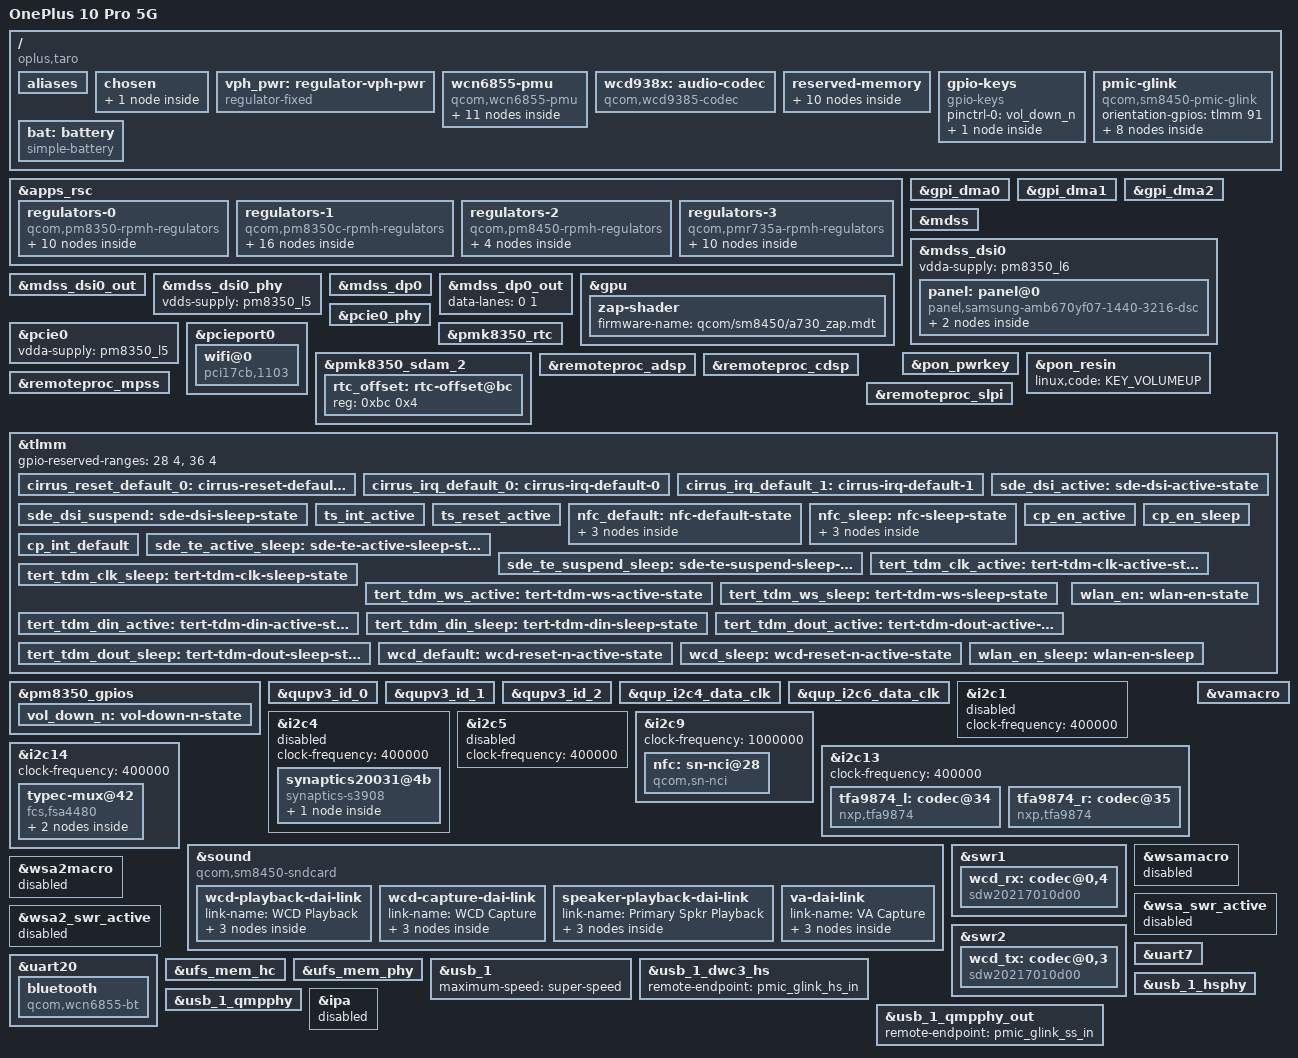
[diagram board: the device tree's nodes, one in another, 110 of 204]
// SPDX-License-Identifier: GPL-2.0-only
/*
 * Copyright (c) 2026, Nazar Kompanets <xlie7669@gmail.com>
*/

/dts-v1/;

#include <dt-bindings/arm/qcom,ids.h>
#include <dt-bindings/pinctrl/qcom,pmic-gpio.h>
#include <dt-bindings/regulator/qcom,rpmh-regulator.h>

#include "sm8450.dtsi"
#include "pm8350.dtsi"
#include "pm8350b.dtsi"
#include "pm8350c.dtsi"
#include "pm8450.dtsi"
#include "pmk8350.dtsi"
#include "pmr735a.dtsi"

/delete-node/ &cdsp_secure_heap;
/delete-node/ &video_mem;
/delete-node/ &adsp_mem;
/delete-node/ &slpi_mem;
/delete-node/ &mte_mem;
/delete-node/ &rmtfs_mem;

/ {
	model = "OnePlus 10 Pro 5G";
	compatible = "oplus,taro", "qcom,sm8450";

	chassis-type = "handset";

	/* required for bootloader to select correct board */
	qcom,msm-id = <QCOM_ID_SM8450 0x20000>; /* SM8450 v2.0 */
	qcom,board-id = <0x10008 0>;

	aliases {
		hsuart0 = &uart20;
		serial0 = &uart7;
	};

	chosen {
		#address-cells = <2>;
		#size-cells = <2>;
		ranges;

		bootargs = "earlycon clk_ignore_unused pd_ignore_unused";
		stdout-path = "serial0:115200n8";

		framebuffer: framebuffer@b8000000 {
			compatible = "simple-framebuffer";
			reg = <0x0 0xb8000000 0x0 0x2b00000>;
			width = <1080>;
			height = <2340>;
			stride = <(1080 * 4)>;
			format = "a8r8g8b8";
		};

	};

	vph_pwr: regulator-vph-pwr {
		compatible = "regulator-fixed";
		regulator-name = "vph_pwr";
		regulator-min-microvolt = <3700000>;
		regulator-max-microvolt = <3700000>;
		regulator-always-on;
		regulator-boot-on;
	};

	wcn6855-pmu {
		compatible = "qcom,wcn6855-pmu";

		pinctrl-0 = <&wlan_en>;
		pinctrl-1 = <&wlan_en_sleep>;
		pinctrl-names = "default", "sleep";

		wlan-enable-gpios = <&tlmm 80 GPIO_ACTIVE_HIGH>;
		bt-enable-gpios = <&tlmm 81 GPIO_ACTIVE_HIGH>;
		swctrl-gpios = <&tlmm 82 GPIO_ACTIVE_HIGH>;

		vddio-supply = <&pm8350_s10>;
		vddaon-supply = <&pmr735a_s2>;
		vddpmu-supply = <&pm8350_s11>;
		vddrfa0p95-supply = <&pm8350_s11>;
		vddrfa1p3-supply = <&pm8350_s12>;
		vddrfa1p9-supply = <&pm8350c_s1>;
		vddpcie1p3-supply = <&pm8350_s12>;
		vddpcie1p9-supply = <&pm8350c_s1>;

		regulators {
			vreg_pmu_rfa_cmn_0p8: ldo0 {
				regulator-name = "vreg_pmu_rfa_cmn_0p8";
			};

			vreg_pmu_aon_0p8: ldo1 {
				regulator-name = "vreg_pmu_aon_0p8";
			};

			vreg_pmu_wlcx_0p8: ldo2 {
				regulator-name = "vreg_pmu_wlcx_0p8";
			};

			vreg_pmu_wlmx_0p8: ldo3 {
				regulator-name = "vreg_pmu_wlmx_0p8";
			};

			vreg_pmu_btcmx_0p8: ldo4 {
				regulator-name = "vreg_pmu_btcmx_0p8";
			};

			vreg_pmu_pcie_1p8: ldo5 {
				regulator-name = "vreg_pmu_pcie_1p8";
			};

			vreg_pmu_pcie_0p9: ldo6 {
				regulator-name = "vreg_pmu_pcie_0p9";
			};

			vreg_pmu_rfa_0p8: ldo7 {
				regulator-name = "vreg_pmu_rfa_0p8";
			};

			vreg_pmu_rfa_1p2: ldo8 {
				regulator-name = "vreg_pmu_rfa_1p2";
			};

			vreg_pmu_rfa_1p7: ldo9 {
				regulator-name = "vreg_pmu_rfa_1p7";
			};
		};
	};

	wcd938x: audio-codec {
		compatible = "qcom,wcd9385-codec";

		pinctrl-names = "default", "sleep";
		pinctrl-0 = <&wcd_default>;
		pinctrl-1 = <&wcd_sleep>;

		qcom,micbias1-microvolt = <1800000>;
		qcom,micbias2-microvolt = <2700000>;
		qcom,micbias3-microvolt = <1800000>;
		qcom,micbias4-microvolt = <1800000>;
		qcom,mbhc-buttons-vthreshold-microvolt = <75000 150000 237000 500000 500000 500000 500000 500000>;
		qcom,mbhc-headset-vthreshold-microvolt = <1700000>;
		qcom,mbhc-headphone-vthreshold-microvolt = <50000>;
		qcom,rx-device = <&wcd_rx>;
		qcom,tx-device = <&wcd_tx>;

		reset-gpios = <&tlmm 43 GPIO_ACTIVE_LOW>;

		vdd-buck-supply = <&pm8350_s10>;
		vdd-rxtx-supply = <&pm8350_s10>;
		vdd-io-supply = <&pm8350_s10>;
		vdd-mic-bias-supply = <&vreg_bob>;

		#sound-dai-cells = <1>;
	};

	reserved-memory {

		cdsp_secure_heap: memory@80c00000 {
			reg = <0x0 0x80c00000 0x0 0x100000>;
			no-map;
		};

		video_mem: memory@85700000 {
			reg = <0x0 0x9fd00000 0x0 0x700000>;
			no-map;
		};

		adsp_mem: adsp_region@85e00000 {
			reg = <0x0 0x85700000 0x0 0x2800000>;
			no-map;
		};

		slpi_mem: memory@87f00000 {
			reg = <0x0 0x87f00000 0x0 0x1a00000>;
			no-map;
		};

		ramoops@a1f00000 {
			compatible = "ramoops";
			reg = <0 0xa1f00000 0x0 0x100000>;
			console-size = <0x40000>;
			no-map;
		};

		dump_device_info_mem: memory@a4f00000 {
			reg = <0x0 0xa4f00000 0x0 0x8000>;
			no-map;
		};

		bootloader_log_mem: memory@a7605000 {
			reg = <0x0 0xa7605000 0x0 0x8000>;
		};

		mte_mem: memory@c0000000 {
			reg = <0x0 0xc0000000 0x0 0x20000000>;
			no-map;
		};

		/*
		 * The bootloader will only keep display hardware enabled
		 * if this memory region is named exactly 'splash_region'
		 */

		splash_memory: splash_region@b8000000 {
			reg = <0x0 0xb8000000 0x0 0x2b00000>;
			no-map;
		};

		/*
		 * The rmtfs memory region in downstream is 'dynamically allocated'
		 * but given the same address every time. Hard code it as this address is
		 * where the modem firmware expects it to be.
		 */
		rmtfs_mem: memory@e6f00000 {
			compatible = "qcom,rmtfs-mem";
			reg = <0x0 0xe6f00000 0x0 0x280000>;
			no-map;

			qcom,client-id = <1>;
			qcom,vmid = <QCOM_SCM_VMID_MSS_MSA>;
		};

	};

	gpio-keys {
		compatible = "gpio-keys";

		pinctrl-0 = <&vol_down_n>;
		pinctrl-names = "default";

		key-volume-down {
			label = "Volume Down";
			linux,code = <KEY_VOLUMEDOWN>;
			gpios = <&pm8350_gpios 6 GPIO_ACTIVE_LOW>;
			debounce-interval = <15>;
			linux,can-disable;
			wakeup-source;
		};
	};

	pmic-glink {
		compatible = "qcom,sm8450-pmic-glink", "qcom,pmic-glink";
		#address-cells = <1>;
		#size-cells = <0>;
		orientation-gpios = <&tlmm 91 GPIO_ACTIVE_HIGH>;

		connector@0 {
			compatible = "usb-c-connector";
			reg = <0>;
			power-role = "dual";
			data-role = "dual";

			ports {
				#address-cells = <1>;
				#size-cells = <0>;

				port@0 {
					reg = <0>;

					pmic_glink_hs_in: endpoint {
						remote-endpoint = <&usb_1_dwc3_hs>;
					};
				};

				port@1 {
					reg = <1>;

					pmic_glink_ss_in: endpoint {
						remote-endpoint = <&usb_1_qmpphy_out>;
					};
				};

				port@2 {
					reg = <2>;

					pmic_glink_sbu: endpoint {
						remote-endpoint = <&fsa4480_sbu_mux>;
					};
				};

			};
		};
	};

	bat: battery {
		compatible = "simple-battery";
		charge-full-design-microamp-hours = <5000000>;
		voltage-min-design-microvolt = <3855000>;
		voltage-max-design-microvolt = <4435000>;
	};

};

&apps_rsc {
	regulators-0 {
		compatible = "qcom,pm8350-rpmh-regulators";
		qcom,pmic-id = "b";

		vdd-s1-supply = <&vph_pwr>;
		vdd-s2-supply = <&vph_pwr>;
		vdd-s3-supply = <&vph_pwr>;
		vdd-s4-supply = <&vph_pwr>;
		vdd-s5-supply = <&vph_pwr>;
		vdd-s6-supply = <&vph_pwr>;
		vdd-s7-supply = <&vph_pwr>;
		vdd-s8-supply = <&vph_pwr>;
		vdd-s9-supply = <&vph_pwr>;
		vdd-s10-supply = <&vph_pwr>;
		vdd-s11-supply = <&vph_pwr>;
		vdd-s12-supply = <&vph_pwr>;

		vdd-l1-l4-supply = <&pm8350_s11>;
		vdd-l2-l7-supply = <&vreg_bob>;
		vdd-l3-l5-supply = <&vreg_bob>;
		vdd-l6-l9-l10-supply = <&pm8350_s12>;

		/*
		 * ARC regulators:
		 * s5 - gfx.lvl
		 * l8 - lcx.lvl
		 */

		pm8350_s10: smps10 {
			regulator-name = "pm8350_s10";
			regulator-min-microvolt = <1800000>;
			regulator-max-microvolt = <1800000>;
		};

		pm8350_s11: smps11 {
			regulator-name = "pm8350_s11";
			regulator-min-microvolt = <848000>;
			regulator-max-microvolt = <1104000>;
		};

		pm8350_s12: smps12 {
			regulator-name = "pm8350_s12";
			regulator-min-microvolt = <1224000>;
			regulator-max-microvolt = <1400000>;
		};

		pm8350_l1: ldo1 {
			regulator-name = "pm8350_l1";
			regulator-min-microvolt = <912000>;
			regulator-max-microvolt = <920000>;
			regulator-initial-mode = <RPMH_REGULATOR_MODE_HPM>;
		};

		pm8350_l2: ldo2 {
			regulator-name = "pm8350_l2";
			regulator-min-microvolt = <3072000>;
			regulator-max-microvolt = <3072000>;
			regulator-initial-mode = <RPMH_REGULATOR_MODE_HPM>;
		};

		pm8350_l3: ldo3 {
			regulator-name = "pm8350_l3";
			regulator-min-microvolt = <904000>;
			regulator-max-microvolt = <904000>;
			regulator-initial-mode = <RPMH_REGULATOR_MODE_HPM>;
		};

		pm8350_l5: ldo5 {
			regulator-name = "pm8350_l5";
			regulator-min-microvolt = <880000>;
			regulator-max-microvolt = <912000>;
			regulator-initial-mode = <RPMH_REGULATOR_MODE_HPM>;
		};

		pm8350_l6: ldo6 {
			regulator-name = "pm8350_l6";
			regulator-min-microvolt = <1200000>;
			regulator-max-microvolt = <1200000>;
			regulator-initial-mode = <RPMH_REGULATOR_MODE_HPM>;
		};

		pm8350_l7: ldo7 {
			regulator-name = "pm8350_l7";
			regulator-min-microvolt = <2504000>;
			regulator-max-microvolt = <2504000>;
			regulator-initial-mode = <RPMH_REGULATOR_MODE_HPM>;
		};

		pm8350_l9: ldo9 {
			regulator-name = "pm8350_l9";
			regulator-min-microvolt = <1200000>;
			regulator-max-microvolt = <1200000>;
			regulator-initial-mode = <RPMH_REGULATOR_MODE_HPM>;
		};
	};

	regulators-1 {
		compatible = "qcom,pm8350c-rpmh-regulators";
		qcom,pmic-id = "c";

		vdd-s1-supply = <&vph_pwr>;
		vdd-s2-supply = <&vph_pwr>;
		vdd-s3-supply = <&vph_pwr>;
		vdd-s4-supply = <&vph_pwr>;
		vdd-s5-supply = <&vph_pwr>;
		vdd-s6-supply = <&vph_pwr>;
		vdd-s7-supply = <&vph_pwr>;
		vdd-s8-supply = <&vph_pwr>;
		vdd-s9-supply = <&vph_pwr>;
		vdd-s10-supply = <&vph_pwr>;

		vdd-l1-l12-supply = <&vreg_bob>;
		vdd-l2-l8-supply = <&vreg_bob>;
		vdd-l3-l4-l5-l7-l13-supply = <&vreg_bob>;
		vdd-l6-l9-l11-supply = <&vreg_bob>;
		vdd-l10-supply = <&pm8350_s12>;

		vdd-bob-supply = <&vph_pwr>;

		/*
		 * ARC regulators:
		 * s2 - mxc.lvl
		 * s4 - mss.lvl
		 * s6 - cx.lvl
		 */

		pm8350c_s1: smps1 {
			regulator-name = "pm8350c_s1";
			regulator-min-microvolt = <1800000>;
			regulator-max-microvolt = <2024000>;
		};

		pm8350c_s10: smps10 {
			regulator-name = "pm8350c_s10";
			regulator-min-microvolt = <1000000>;
			regulator-max-microvolt = <1100000>;
		};

		vreg_bob: bob {
			regulator-name = "vreg_bob";
			regulator-min-microvolt = <3008000>;
			regulator-max-microvolt = <3960000>;
			regulator-initial-mode = <RPMH_REGULATOR_MODE_AUTO>;
		};

		pm8350c_l1: ldo1 {
			regulator-name = "pm8350c_l1";
			regulator-min-microvolt = <1800000>;
			regulator-max-microvolt = <1800000>;
			regulator-initial-mode = <RPMH_REGULATOR_MODE_HPM>;
		};

		pm8350c_l2: ldo2 {
			regulator-name = "pm8350c_l2";
			regulator-min-microvolt = <1800000>;
			regulator-max-microvolt = <1800000>;
			regulator-initial-mode = <RPMH_REGULATOR_MODE_HPM>;
		};

		pm8350c_l3: ldo3 {
			regulator-name = "pm8350c_l3";
			regulator-min-microvolt = <2800000>;
			regulator-max-microvolt = <3008000>;
			regulator-initial-mode = <RPMH_REGULATOR_MODE_HPM>;
		};

		pm8350c_l4: ldo4 {
			regulator-name = "pm8350c_l4";
			regulator-min-microvolt = <1704000>;
			regulator-max-microvolt = <3000000>;
			regulator-initial-mode = <RPMH_REGULATOR_MODE_HPM>;
		};

		pm8350c_l5: ldo5 {
			regulator-name = "pm8350c_l5";
			regulator-min-microvolt = <1704000>;
			regulator-max-microvolt = <3000000>;
			regulator-initial-mode = <RPMH_REGULATOR_MODE_HPM>;
		};

		pm8350c_l6: ldo6 {
			regulator-name = "pm8350c_l6";
			regulator-min-microvolt = <1800000>;
			regulator-max-microvolt = <1800000>;
			regulator-initial-mode = <RPMH_REGULATOR_MODE_HPM>;
		};

		pm8350c_l7: ldo7 {
			regulator-name = "pm8350c_l7";
			regulator-min-microvolt = <3008000>;
			regulator-max-microvolt = <3008000>;
			regulator-initial-mode = <RPMH_REGULATOR_MODE_HPM>;
		};

		pm8350c_l8: ldo8 {
			regulator-name = "pm8350c_l8";
			regulator-min-microvolt = <1800000>;
			regulator-max-microvolt = <1800000>;
			regulator-initial-mode = <RPMH_REGULATOR_MODE_HPM>;
		};

		pm8350c_l9: ldo9 {
			regulator-name = "pm8350c_l9";
			regulator-min-microvolt = <2960000>;
			regulator-max-microvolt = <3008000>;
			regulator-initial-mode = <RPMH_REGULATOR_MODE_HPM>;
		};

		pm8350c_l10: ldo10 {
			regulator-name = "pm8350c_l10";
			regulator-min-microvolt = <1200000>;
			regulator-max-microvolt = <1200000>;
			regulator-initial-mode = <RPMH_REGULATOR_MODE_HPM>;
		};

		pm8350c_l11: ldo11 {
			regulator-name = "pm8350c_l11";
			regulator-min-microvolt = <2400000>;
			regulator-max-microvolt = <3008000>;
			regulator-initial-mode = <RPMH_REGULATOR_MODE_HPM>;
		};

		pm8350c_l12: ldo12 {
			regulator-name = "pm8350c_l12";
			regulator-min-microvolt = <1800000>;
			regulator-max-microvolt = <1800000>;
			regulator-initial-mode = <RPMH_REGULATOR_MODE_HPM>;
		};

		pm8350c_l13: ldo13 {
			regulator-name = "pm8350c_l13";
			regulator-min-microvolt = <3000000>;
			regulator-max-microvolt = <3000000>;
			regulator-initial-mode = <RPMH_REGULATOR_MODE_HPM>;
		};
	};

	regulators-2 {
		compatible = "qcom,pm8450-rpmh-regulators";
		qcom,pmic-id = "h";

		vdd-s1-supply = <&vph_pwr>;
		vdd-s2-supply = <&vph_pwr>;
		vdd-s3-supply = <&vph_pwr>;
		vdd-s4-supply = <&vph_pwr>;
		vdd-s5-supply = <&vph_pwr>;
		vdd-s6-supply = <&vph_pwr>;

		vdd-l2-supply = <&vreg_bob>;
		vdd-l3-supply = <&vreg_bob>;
		vdd-l4-supply = <&vreg_bob>;

		/*
		 * ARC regulators:
		 * S2 - ebi.lvl
		 * S4 - mmcx.lvl
		 * S6 - mx.lvl
		 * L1 - lmx.lvl
		 */

		pm8450_s3: smps3 {
			regulator-name = "pm8450_s3";
			regulator-min-microvolt = <500000>;
			regulator-max-microvolt = <600000>;
		};

		pm8450_l2: ldo2 {
			regulator-name = "pm8450_l2";
			regulator-min-microvolt = <880000>;
			regulator-max-microvolt = <912000>;
			regulator-initial-mode = <RPMH_REGULATOR_MODE_HPM>;
		};

		pm8450_l3: ldo3 {
			regulator-name = "pm8450_l3";
			regulator-min-microvolt = <912000>;
			regulator-max-microvolt = <912000>;
			regulator-initial-mode = <RPMH_REGULATOR_MODE_HPM>;
		};

		pm8450_l4: ldo4 {
			regulator-name = "pm8450_l4";
			regulator-min-microvolt = <1800000>;
			regulator-max-microvolt = <1800000>;
			regulator-initial-mode = <RPMH_REGULATOR_MODE_HPM>;
		};
	};

	regulators-3 {
		compatible = "qcom,pmr735a-rpmh-regulators";
		qcom,pmic-id = "e";

		vdd-s1-supply = <&vph_pwr>;
		vdd-s2-supply = <&vph_pwr>;
		vdd-s3-supply = <&vph_pwr>;

		vdd-l1-l2-supply = <&pmr735a_s2>;
		vdd-l3-supply = <&pmr735a_s1>;
		vdd-l4-supply = <&pm8350c_s1>;
		vdd-l5-l6-supply = <&pm8350c_s1>;
		vdd-l7-bob-supply = <&vreg_bob>;

		pmr735a_s1: smps1 {
			regulator-name = "pmr735a_s1";
			regulator-min-microvolt = <1200000>;
			regulator-max-microvolt = <1296000>;
		};

		pmr735a_s2: smps2 {
			regulator-name = "pmr735a_s2";
			regulator-min-microvolt = <500000>;
			regulator-max-microvolt = <1040000>;
		};

		pmr735a_s3: smps3 {
			regulator-name = "pmr735a_s3";
			regulator-min-microvolt = <435000>;
			regulator-max-microvolt = <2352000>;
		};

		pmr735a_l1: ldo1 {
			regulator-name = "pmr735a_l1";
			regulator-min-microvolt = <800000>;
			regulator-max-microvolt = <800000>;
		};

		pmr735a_l2: ldo2 {
			regulator-name = "pmr735a_l2";
			regulator-min-microvolt = <480000>;
			regulator-max-microvolt = <912000>;
		};

		pmr735a_l3: ldo3 {
			regulator-name = "pmr735a_l3";
			regulator-min-microvolt = <1200000>;
			regulator-max-microvolt = <1200000>;
		};

		pmr735a_l4: ldo4 {
			regulator-name = "pmr735a_l4";
			regulator-min-microvolt = <1776000>;
			regulator-max-microvolt = <1776000>;
		};

		pmr735a_l5: ldo5 {
			regulator-name = "pmr735a_l5";
			regulator-min-microvolt = <880000>;
			regulator-max-microvolt = <880000>;
		};

		pmr735a_l6: ldo6 {
			regulator-name = "pmr735a_l6";
			regulator-min-microvolt = <1200000>;
			regulator-max-microvolt = <1200000>;
		};

		pmr735a_l7: ldo7 {
			regulator-name = "pmr735a_l7";
			regulator-min-microvolt = <2800000>;
			regulator-max-microvolt = <2800000>;
		};
	};
};

&gpi_dma0 {
	status = "okay";
};

&gpi_dma1 {
	status = "okay";
};

&gpi_dma2 {
	status = "okay";
};


&mdss {
	status = "okay";
};

&mdss_dsi0 {
	vdda-supply = <&pm8350_l6>;
	status = "okay";

	panel: panel@0 {
		compatible = "panel,samsung-amb670yf07-1440-3216-dsc";
		reg = <0>;

		reset-gpios = <&tlmm 0 GPIO_ACTIVE_LOW>;
		te-gpios = <&tlmm 86 GPIO_ACTIVE_LOW>;

		pinctrl-0 = <&sde_dsi_active &sde_te_active_sleep>;
		pinctrl-1 = <&sde_dsi_suspend &sde_te_suspend_sleep>;
		pinctrl-names = "default", "sleep";

		vddd-supply = <&pm8350c_l10>;
		vci-supply = <&pm8350c_l13>;
		vddio-supply = <&pm8350c_l12>;

		port {
			panel_in: endpoint {
				remote-endpoint = <&mdss_dsi0_out>;
			};
		};
	};
};

&mdss_dsi0_out {
	data-lanes = <0 1 2 3>;
	remote-endpoint = <&panel_in>;
};

&mdss_dsi0_phy {
	vdds-supply = <&pm8350_l5>;
	status = "okay";
};

&mdss_dp0 {
	status = "okay";
};

&mdss_dp0_out {
	data-lanes = <0 1>;
};

&gpu {
	status = "okay";

	/* fails to load a730_zap.mbn so GPU still works only with a730_zap.mdt */
	zap-shader {
		firmware-name = "qcom/sm8450/a730_zap.mdt";
	};
};

&pcie0 {
	status = "okay";
	// vddpe-3v3-supply = <&wcn6855_pmu>;
	vdda-supply = <&pm8350_l5>;
};

&pcieport0 {
	wifi@0 {
		compatible = "pci17cb,1103";
		reg = <0x10000 0x0 0x0 0x0 0x0>;

		vddrfacmn-supply = <&vreg_pmu_rfa_cmn_0p8>;
		vddaon-supply = <&vreg_pmu_aon_0p8>;
		vddwlcx-supply = <&vreg_pmu_wlcx_0p8>;
		vddwlmx-supply = <&vreg_pmu_wlmx_0p8>;
		vddpcie1p8-supply = <&vreg_pmu_pcie_1p8>;
		vddpcie0p9-supply = <&vreg_pmu_pcie_0p9>;
		vddrfa0p8-supply = <&vreg_pmu_rfa_0p8>;
		vddrfa1p2-supply = <&vreg_pmu_rfa_1p2>;
		vddrfa1p8-supply = <&vreg_pmu_rfa_1p7>;
	};
};

&pcie0_phy {
	vdda-phy-supply = <&pm8350_l5>;
	vdda-pll-supply = <&pm8350_l6>;
	status = "okay";
};

&pmk8350_rtc {
	nvmem-cells = <&rtc_offset>;
	nvmem-cell-names = "offset";

	status = "okay";
};

&pmk8350_sdam_2 {
	status = "okay";

	rtc_offset: rtc-offset@bc {
		reg = <0xbc 0x4>;
	};
};

&pon_pwrkey {
	status = "okay";
};

&pon_resin {
	linux,code = <KEY_VOLUMEUP>;
	status = "okay";
};

&remoteproc_adsp {
	status = "okay";
};

&remoteproc_cdsp {
	status = "okay";
};

&remoteproc_mpss {
	status = "okay";
};

&remoteproc_slpi {
	status = "okay";
};

&tlmm {
	gpio-reserved-ranges = <28 4>, <36 4>;

	cirrus_reset_default_0: cirrus-reset-default-0 {
		pins = "gpio1";
		function = "gpio";
		drive-strength = <16>;
		bias-disable;
		output-high;
	};

	cirrus_irq_default_0: cirrus-irq-default-0 {
		pins = "gpio118";
		function = "gpio";
		drive-strength = <2>;
		bias-pull-up;
	};

	cirrus_irq_default_1: cirrus-irq-default-1 {
		pins = "gpio63";
		function = "gpio";
		drive-strength = <2>;
		bias-pull-up;
	};

	sde_dsi_active: sde-dsi-active-state {
		pins = "gpio3";
		function = "gpio";
		drive-strength = <8>;
		bias-disable;
	};

	sde_dsi_suspend: sde-dsi-sleep-state {
		pins = "gpio3";
		function = "gpio";
		drive-strength = <2>;
		bias-pull-down;
	};

	ts_int_active: ts_int_active {
		pins = "gpio21";
		function = "gpio";
		drive-strength = <8>;
		bias-disable;
		input-enable;
	};

	ts_reset_active: ts_reset_active {
		pins = "gpio20";
		function = "gpio";
		drive-strength = <8>;
		output-low;
		bias-disable;

	};

	nfc_default: nfc-default-state {
		nfc_int_active: nfc_int_active-state {
			pins = "gpio46";
			function = "gpio";
			drive-strength = <2>;
			bias-pull-up;
		};

		nfc_enable_active: nfc_enable_active-state {
			pins = "gpio34";
			function = "gpio";
			drive-strength = <2>;
			bias-pull-up;
		};

		nfc_clk_req_active: nfc_clk_req_active-state {
			pins = "gpio35";
			function = "gpio";
			drive-strength = <2>;
			bias-pull-up;
		};
	};

	nfc_sleep: nfc-sleep-state {
		nfc_int_suspend: nfc_int_suspend-state {
			pins = "gpio46";
			function = "gpio";
			drive-strength = <2>;
			bias-pull-up;
		};

		nfc_enable_suspend: nfc_enable_suspend-state {
			pins = "gpio34";
			function = "gpio";
			drive-strength = <2>;
			bias-disable;
		};

		nfc_clk_req_suspend: nfc_clk_req_suspend-state {
			pins = "gpio35";
			function = "gpio";
			drive-strength = <2>;
			bias-disable;
		};
	};

	cp_en_active: cp_en_active {
		pins = "gpio70";
		function = "gpio";
		drive-strength = <2>;
		bias-disable;
		output-high;
	};

	cp_en_sleep: cp_en_sleep {
		pins = "gpio70";
		function = "gpio";
		drive-strength = <2>;
		bias-disable;
		output-high;
	};

	cp_int_default: cp_int_default {
		pins = "gpio44";
		function = "gpio";
		drive-strength = <2>;
		bias-pull-down;
		input-enable;
	};


	sde_te_active_sleep: sde-te-active-sleep-state {
		pins = "gpio86";
		function = "mdp_vsync";
		drive-strength = <2>;
		bias-pull-down;
	};

	sde_te_suspend_sleep: sde-te-suspend-sleep-state {
		pins = "gpio86";
		function = "mdp_vsync";
		drive-strength = <2>;
		bias-pull-down;
	};

	tert_tdm_clk_active: tert-tdm-clk-active-state {
		pins = "gpio121";
		function = "mi2s2_sck";
		drive-strength = <6>;
		bias-disable;
		output-high;
	};

	tert_tdm_clk_sleep: tert-tdm-clk-sleep-state {
		pins = "gpio121";
		function = "gpio";
		drive-strength = <2>;
		bias-pull-down;
	};

	tert_tdm_ws_active: tert-tdm-ws-active-state {
		pins = "gpio123";
		function = "mi2s2_ws";
		drive-strength = <8>;
		bias-disable;
		output-high;
	};

	tert_tdm_ws_sleep: tert-tdm-ws-sleep-state {
		pins = "gpio123";
		function = "gpio";
		drive-strength = <2>;
		bias-pull-down;
	};

	tert_tdm_din_active: tert-tdm-din-active-state {
		pins = "gpio122";
		function = "mi2s2_data0";
		drive-strength = <8>;
		bias-disable;
	};

	tert_tdm_din_sleep: tert-tdm-din-sleep-state {
		pins = "gpio122";
		function = "gpio";
		drive-strength = <2>;
		bias-pull-down;
	};

	tert_tdm_dout_active: tert-tdm-dout-active-state {
		pins = "gpio124";
		function = "mi2s2_data1";
		drive-strength = <8>;
		bias-disable;
	};

	tert_tdm_dout_sleep: tert-tdm-dout-sleep-state {
		pins = "gpio124";
		function = "gpio";
		drive-strength = <2>;
		bias-pull-down;
	};

	wcd_default: wcd-reset-n-active-state {
		pins = "gpio43";
		function = "gpio";
		drive-strength = <16>;
		bias-disable;
		output-high;
	};

	wcd_sleep: wcd-reset-n-active-state {
		pins = "gpio43";
		function = "gpio";
		drive-strength = <16>;
		bias-disable;
		output-low;
	};

	wlan_en: wlan-en-state {
		pins = "gpio80";
		function = "gpio";
		drive-strength = <16>;
		bias-pull-up;
		output-high;
	};

	wlan_en_sleep: wlan-en-sleep {
		pins = "gpio80";
		function = "gpio";
		drive-strength = <2>;
		bias-pull-down;
		output-low;
	};
};

&pm8350_gpios {
	vol_down_n: vol-down-n-state {
		pins = "gpio6";
		function = "normal";
		power-source = <1>;
		bias-pull-up;
	};
};

&qupv3_id_0 {
	status = "okay";
};

&qupv3_id_1 {
	status = "okay";
};

&qupv3_id_2 {
	status = "okay";
};

&qup_i2c4_data_clk {
	drive-strength = <2>;
	bias-pull-up;
};

&qup_i2c6_data_clk {
	drive-strength = <2>;
	bias-pull-up;
};

&i2c1 {
	clock-frequency = <400000>;
 	status = "disabled";

	/* for hl7227 charger and p9415 wireless charger  */
};

&i2c4 {
	clock-frequency = <400000>;
	status = "disabled";

	synaptics20031@4b {
		compatible = "synaptics-s3908";
		reg = <0x4b>;
		chip-name = "S3908";

		/* Interrupt && Irq-gpio */
		interrupt-parent = <&tlmm>;
		interrupts = <21 0x2008>;

		/* Power Config */
		//enable2v8_gpio = <&tlmm 26 0x1>;
		enable1v8_gpio = <&tlmm 186 GPIO_ACTIVE_LOW>;
		vdd_2v8-supply = <&pm8350c_l3>;
		vcc_1v8-supply = <&pm8350c_l6>;
		vdd_2v8_volt = <3008000>;

		/* Other HW Resource */
		irq-gpio = <&tlmm 21 0x2008>;
		reset-gpio = <&tlmm 20 GPIO_ACTIVE_LOW>;
		pinctrl-names = "default";
		pinctrl-0 = <&ts_int_active &ts_reset_active>;

		touchpanel,max-num-support = <10>;
		touchpanel,tx-rx-num = <17 38>;
		earsense,tx-rx-num = <17 18>;
		touchpanel,panel-coords = <5760 12864>;
		touchpanel,display-coords = <1440 3216>;
		touchpanel,touchmajor-limit = <256 256>;
		touchpanel,int-mode = <1>; /*0: interrupt and disable, 1:interrupt and not disable*/
		touchpanel,curved-size = <45>;

		touchpanel,smooth-level = <0 1 2 4 7 9>;
		touchpanel,smooth-level-charging = <0 2 4 7 8 9>;
		touchpanel,sensitive-level = <0 70 55 40 25 10>;
		touchpanel,single-optimized-time = <8>;
		touchpanel,high-frame-rate-time = <60>;

		end_stretch_value = <480 250 16 16>;
		touchpanel,tp_ic_type = <2>;

		touchpanel,button-type = <4>;
		touchpanel.button-TRx = <0 0>;

		S3908 {
			report_rate_default = <60>;
			report_rate_game_value = <2>;
			default_gesture_mask = <8191>;
		};

	};
};

&i2c5 {
	clock-frequency = <400000>;
	status = "disabled";

	/* pm8008j @ c */
	/* pm8008j @ d */
};

&i2c9 {
	clock-frequency = <1000000>;
	status = "okay";

	nfc: sn-nci@28 {
		compatible = "qcom,sn-nci", "nxp,nxp-nci-i2c";
		reg = <0x28>;
		qcom,sn-irq = <&tlmm 46 GPIO_ACTIVE_LOW>;
		enable-gpios = <&tlmm 34 GPIO_ACTIVE_LOW>;
		qcom,sn-clkreq = <&tlmm 35 GPIO_ACTIVE_LOW>;
		interrupt-parent = <&tlmm>;
		interrupts = <46 0>;
		interrupt-names = "nfc_irq";
		pinctrl-names = "default", "sleep";
		pinctrl-0 = <&nfc_default>;
		pinctrl-1 = <&nfc_sleep>;
	};
};

&i2c13 {
	clock-frequency = <400000>;
	status = "okay";

	tfa9874_l: codec@34 { /* Top Speaker */
		compatible = "nxp,tfa9874";
		reg = <0x34>;
		reset-gpio = <&tlmm 50 GPIO_ACTIVE_HIGH>;
		sound-name-prefix = "Speaker Left";
		#sound-dai-cells = <1>;
		sound-channel = <0>;
	};

	tfa9874_r: codec@35 { /* Bottom Speaker */
		compatible = "nxp,tfa9874";
		reg = <0x35>;
		reset-gpio = <&tlmm 51 GPIO_ACTIVE_HIGH>;
		sound-name-prefix = "Speaker Right";
		#sound-dai-cells = <1>;
		sound-channel = <1>;
	};
};

&i2c14 {
	clock-frequency = <400000>;
	status = "okay";

	typec-mux@42 {
		compatible = "fcs,fsa4480";
		reg = <0x42>;

		vcc-supply = <&vreg_bob>;
		mode-switch;
		orientation-switch;

		port {
			fsa4480_sbu_mux: endpoint {
				remote-endpoint = <&pmic_glink_sbu>;
			};
		};
	};
};

&sound {
	compatible = "qcom,sm8450-sndcard";
	pinctrl-names = "default", "sleep";
	pinctrl-0 = <&tert_tdm_clk_active &tert_tdm_ws_active
			&tert_tdm_din_active &tert_tdm_dout_active>;
	pinctrl-1 = <&tert_tdm_clk_sleep &tert_tdm_ws_sleep
			&tert_tdm_din_sleep &tert_tdm_dout_sleep>;
	model = "OnePlus-10-Pro";

	audio-routing = "AMIC1", "Analog Mic1",
		"AMIC1", "MIC BIAS1",
		"AMIC2", "Analog Mic2",
		"AMIC2", "MIC BIAS2",
		"AMIC3", "Analog Mic3",
		"AMIC3", "MIC BIAS3",
		"AMIC4", "Analog Mic4",
		"AMIC4", "MIC BIAS3",
		"AMIC5", "Analog Mic5",
		"AMIC5", "MIC BIAS4",
		"VA AMIC1", "Analog Mic1",
		"VA AMIC1", "VA MIC BIAS1",
		"VA AMIC2", "Analog Mic2",
		"VA AMIC2", "VA MIC BIAS2",
		"VA AMIC3", "Analog Mic3",
		"VA AMIC3", "VA MIC BIAS3",
		"VA AMIC4", "Analog Mic4",
		"VA AMIC4", "VA MIC BIAS3",
		"VA AMIC5", "Analog Mic5",
		"VA AMIC5", "VA MIC BIAS4",
		"TX DMIC0", "Digital Mic0",
		"Digital Mic0", "MIC BIAS3",
		"TX DMIC1", "Digital Mic1",
		"Digital Mic1", "MIC BIAS3",
		"TX DMIC2", "Digital Mic2",
		"Digital Mic2", "MIC BIAS1",
		"TX DMIC3", "Digital Mic3",
		"Digital Mic3", "MIC BIAS1",
		"IN1_HPHL", "HPHL_OUT",
		"IN2_HPHR", "HPHR_OUT",
		"IN3_AUX", "AUX_OUT",
		"RX_TX DEC0_INP", "TX DEC0 MUX",
		"RX_TX DEC1_INP", "TX DEC1 MUX",
		"RX_TX DEC2_INP", "TX DEC2 MUX",
		"RX_TX DEC3_INP", "TX DEC3 MUX",
		"TX SWR_INPUT", "WCD_TX_OUTPUT",
		"VA SWR_INPUT", "VA_SWR_CLK",
		"VA SWR_INPUT", "WCD_TX_OUTPUT",
		"VA_AIF1 CAP", "VA_SWR_CLK",
		"VA_AIF2 CAP", "VA_SWR_CLK",
		"VA_AIF3 CAP", "VA_SWR_CLK",
		"VA DMIC0", "Digital Mic0",
		"VA DMIC1", "Digital Mic1",
		"VA DMIC2", "Digital Mic2",
		"VA DMIC3", "Digital Mic3",
		"Digital Mic0", "VA MIC BIAS3",
		"Digital Mic1", "VA MIC BIAS3",
		"Digital Mic2", "VA MIC BIAS1",
		"Digital Mic3", "VA MIC BIAS1";


	wcd-playback-dai-link {
		link-name = "WCD Playback";

		cpu {
			sound-dai = <&q6apmbedai RX_CODEC_DMA_RX_0>;
		};

		codec {
			sound-dai = <&wcd938x 0>, <&swr1 0>, <&rxmacro 0>;
		};

		platform {
			sound-dai = <&q6apm>;
		};
	};

	wcd-capture-dai-link {
		link-name = "WCD Capture";

		cpu {
			sound-dai = <&q6apmbedai TX_CODEC_DMA_TX_3>;
		};

		codec {
			sound-dai = <&wcd938x 1>, <&swr2 0>, <&txmacro 0>;
		};

		platform {
			sound-dai = <&q6apm>;
		};
	};

	speaker-playback-dai-link {
		link-name = "Primary Spkr Playback";

		cpu {
			sound-dai = <&q6apmbedai TERTIARY_TDM_RX_0>;
		};

		codec {
			sound-dai = <&tfa9874_l 0>, <&tfa9874_r 0>;
		};

		platform {
			sound-dai = <&q6apm>;
		};
	};

	va-dai-link {
		link-name = "VA Capture";

		cpu {
			sound-dai = <&q6apmbedai TX_CODEC_DMA_TX_3>;
		};

		codec {
			sound-dai = <&vamacro 0>;
		};

		platform {
			sound-dai = <&q6apm>;
		};
	};
};

&swr1 {
	status = "okay";

	/* WCD9380 RX */
	wcd_rx: codec@0,4 {
		compatible = "sdw20217010d00";
		reg = <0 4>;
		qcom,rx-port-mapping = <1 2 3 4 5>;
	};
};

&swr2 {
	status = "okay";

	/* WCD9380 TX */
	wcd_tx: codec@0,3 {
		compatible = "sdw20217010d00";
		reg = <0 3>;
		qcom,tx-port-mapping = <1 1 2 3>;
	};
};

&vamacro {
	//pinctrl-0 = <&dmic01_default>, <&dmic02_default>;
	//pinctrl-names = "default";
	vdd-micb-supply = <&pm8350_s10>;
	qcom,dmic-sample-rate = <600000>;

	status = "okay";
};

&wsamacro {
	status = "disabled";
};

&wsa2macro {
	status = "disabled";
};

&wsa_swr_active {
	status = "disabled";
};

&wsa2_swr_active {
	status = "disabled";
};

&uart7 {
	status = "okay";
};

&uart20 {
	status = "okay";

	bluetooth {
		compatible = "qcom,wcn6855-bt";

		vddrfacmn-supply = <&vreg_pmu_rfa_cmn_0p8>;
		vddaon-supply = <&vreg_pmu_aon_0p8>;
		vddwlcx-supply = <&vreg_pmu_wlcx_0p8>;
		vddwlmx-supply = <&vreg_pmu_wlmx_0p8>;
		vddbtcmx-supply = <&vreg_pmu_btcmx_0p8>;
		vddrfa0p8-supply = <&vreg_pmu_rfa_0p8>;
		vddrfa1p2-supply = <&vreg_pmu_rfa_1p2>;
		vddrfa1p8-supply = <&vreg_pmu_rfa_1p7>;

		max-speed = <3200000>;
	};
};

&ufs_mem_hc {
	status = "okay";

	reset-gpios = <&tlmm 210 GPIO_ACTIVE_LOW>;

	vcc-supply = <&pm8350_l7>;
	vcc-max-microamp = <1100000>;
	vccq-supply = <&pm8350_l9>;
	vccq-max-microamp = <1200000>;
	vdd-hba-supply = <&pm8350_l9>;
};

&ufs_mem_phy {
	status = "okay";

	vdda-phy-supply = <&pm8350_l5>;
	vdda-pll-supply = <&pm8350_l6>;
};

&usb_1 {
	maximum-speed = "super-speed";
	status = "okay";
};

&usb_1_dwc3_hs {
	remote-endpoint = <&pmic_glink_hs_in>;
};

&usb_1_hsphy {
	vdda-pll-supply = <&pm8350_l5>;
	vdda18-supply = <&pm8350c_l1>;
	vdda33-supply = <&pm8350_l2>;
	status = "okay";
};

&usb_1_qmpphy {
	vdda-phy-supply = <&pm8350_l6>;
	vdda-pll-supply = <&pm8350_l1>;
	status = "okay";
};

&usb_1_qmpphy_out {
	remote-endpoint = <&pmic_glink_ss_in>;
};

&ipa {
	qcom,gsi-loader = "self";
	memory-region = <&ipa_fw_mem>;
	firmware-name = "ipa_fws.mdt";
	status = "disabled";
};
